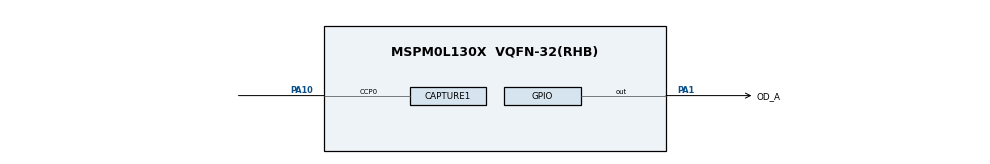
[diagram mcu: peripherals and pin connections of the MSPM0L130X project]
// @cliArgs --device "MSPM0L130X" --package "VQFN-32(RHB)" --part "Default"
// @cliArgs --board /ti/boards/LP_MSPM0L1306 --rtos nortos

/**
 * Import the modules used in this configuration.
 */
const Board    = scripting.addModule("/ti/driverlib/Board");
const CAPTURE  = scripting.addModule("/ti/driverlib/CAPTURE", {}, false);
const CAPTURE1 = CAPTURE.addInstance();
const CAPTURE2 = CAPTURE.addInstance();
const GPIO     = scripting.addModule("/ti/driverlib/GPIO", {}, false);
const GPIO1    = GPIO.addInstance();
const GPIO2    = GPIO.addInstance();
const GPIO3    = GPIO.addInstance();
const TIMER    = scripting.addModule("/ti/driverlib/TIMER", {}, false);
const TIMER1   = TIMER.addInstance();

/**
 * Write custom configuration values to the imported modules.
 */
Board.InitPriority1 = "/ti/driverlib/CAPTURE";

CAPTURE1.captMode                   = "PULSE_WIDTH";
CAPTURE1.timerClkPrescale           = 8;
CAPTURE1.captEdgeDetection          = "FALLING";
CAPTURE1.timerPeriod                = "10ms";
CAPTURE1.interrupts                 = ["CC0_DN","LOAD"];
CAPTURE1.$name                      = "CAPTURE_A";
CAPTURE1.peripheral.$assign         = "TIMG4";
CAPTURE1.peripheral.ccp0Pin.$assign = "PA10";

GPIO1.$name                         = "OW_OUTPUT_A";
GPIO1.associatedPins[0].hiZ         = "ENABLE";
GPIO1.associatedPins[0].$name       = "OD_A";
GPIO1.associatedPins[0].pin.$assign = "PA1";

const SYSCTL = scripting.addModule("/ti/driverlib/SYSCTL", {}, false);
